# CW32L012 register map
Vendor: Wuhan Xinyuan Semiconductor Co.Ltd; Series: ARMCM0P; File version: 1.2
CPU: CM0+ r0p1, little endian, no MPU, no FPU, VTOR, 2 interrupt priority bits
Registers are 32-bit, read-write, no defined reset value unless marked. A register's access mark holds for its fields unless they carry their own. Offsets are from the block's base; [hi:lo] are bit positions; {n}, {i} and the like mark numbered series; 'fields as' and 'values as' point back to an identical list.

## ATIM
Base 0x40001400
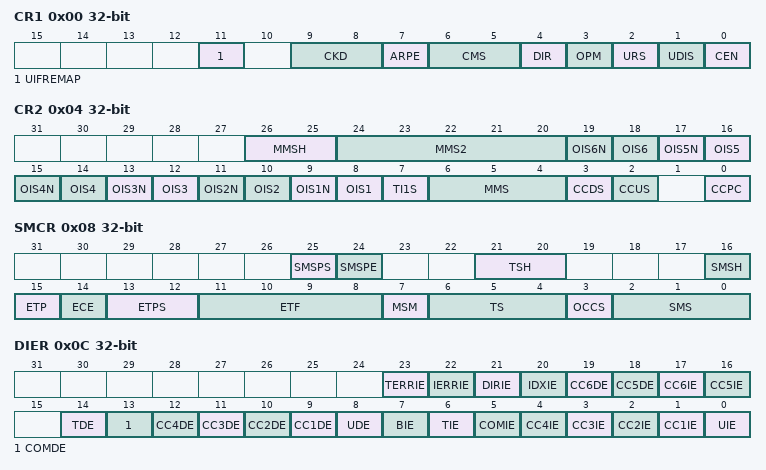
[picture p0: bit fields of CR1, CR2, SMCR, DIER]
0x00 CR1 — Control Register1
  [11] UIFREMAP, [9:8] CKD, [7] ARPE, [6:5] CMS, [4] DIR, [3] OPM, [2] URS, [1] UDIS, [0] CEN
0x04 CR2 — Control Register2
  [26:25] MMSH, [24:20] MMS2, [2n+7] OIS{n}N (n=1..6), [2n+6] OIS{n} (n=1..6), [7] TI1S, [6:4] MMS, [3] CCDS, [2] CCUS, [0] CCPC
0x08 SMCR — Slave Mode Control Register
  [25] SMSPS, [24] SMSPE, [21:20] TSH, [16] SMSH, [15] ETP, [14] ECE, [13:12] ETPS, [11:8] ETF, [7] MSM, [6:4] TS, [3] OCCS, [2:0] SMS
0x0C DIER — Interrupt Enable Register
  [23] TERRIE, [22] IERRIE, [21] DIRIE, [20] IDXIE, [19] CC6DE, [18] CC5DE, [17] CC6IE, [16] CC5IE, [14] TDE, [13] COMDE, [n+8] CC{n}DE (n=1..4), [8] UDE, [7] BIE, [6] TIE, [5] COMIE, [n] CC{n}IE (n=1..4), [0] UIE
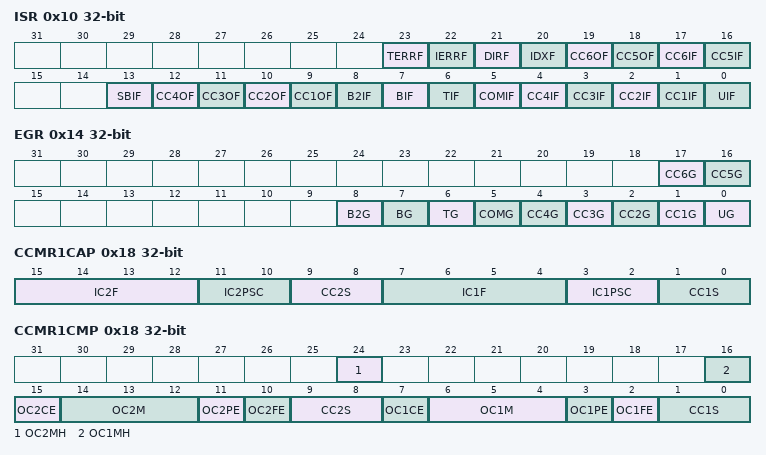
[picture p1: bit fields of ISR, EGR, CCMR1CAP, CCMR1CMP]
0x10 ISR ro — Interrupt status register
  [23] TERRF, [22] IERRF, [21] DIRF, [20] IDXF, [19] CC6OF, [18] CC5OF, [17] CC6IF, [16] CC5IF, [13] SBIF, [n+8] CC{n}OF (n=1..4), [8] B2IF, [7] BIF, [6] TIF, [5] COMIF, [n] CC{n}IF (n=1..4), [0] UIF
0x14 EGR — Event generation register
  [17] CC6G, [16] CC5G, [8] B2G, [7] BG, [6] TG, [5] COMG, [n] CC{n}G (n=1..4), [0] UG
0x18 CCMR1CAP — capture compare mode register 1
  [15:12] IC2F, [11:10] IC2PSC, [9:8] CC2S, [7:4] IC1F, [3:2] IC1PSC, [1:0] CC1S
0x18 CCMR1CMP (alternate view of CCMR1CAP) — capture compare mode register 1
  [24] OC2MH, [16] OC1MH, [15] OC2CE, [14:12] OC2M, [11] OC2PE, [10] OC2FE, [9:8] CC2S, [7] OC1CE, [6:4] OC1M, [3] OC1PE, [2] OC1FE, [1:0] CC1S
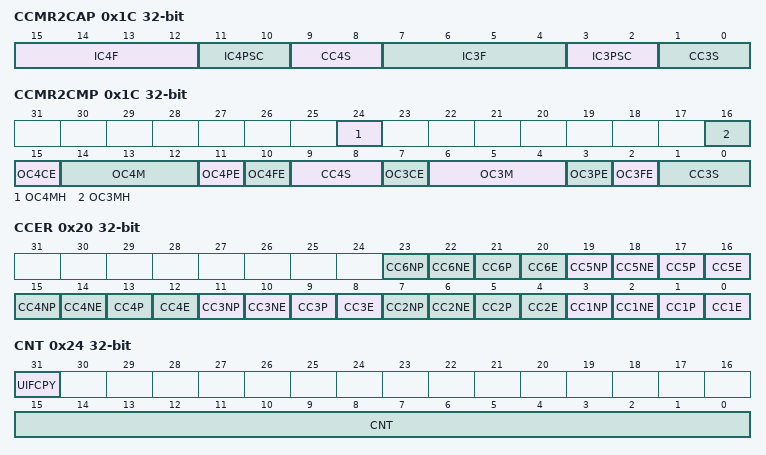
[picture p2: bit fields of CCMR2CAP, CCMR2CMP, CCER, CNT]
0x1C CCMR2CAP — capture compare mode register 2
  [15:12] IC4F, [11:10] IC4PSC, [9:8] CC4S, [7:4] IC3F, [3:2] IC3PSC, [1:0] CC3S
0x1C CCMR2CMP (alternate view of CCMR2CAP) — capture compare mode register 2
  [24] OC4MH, [16] OC3MH, [15] OC4CE, [14:12] OC4M, [11] OC4PE, [10] OC4FE, [9:8] CC4S, [7] OC3CE, [6:4] OC3M, [3] OC3PE, [2] OC3FE, [1:0] CC3S
0x20 CCER — capture compare enable register
  [4n-1] CC{n}NP (n=1..6), [4n-2] CC{n}NE (n=1..6), [4n-3] CC{n}P (n=1..6), [4n-4] CC{n}E (n=1..6)
0x24 CNT — Counter Register
  [31] UIFCPY ro, [15:0] CNT
0x28 PSC — prescaler Register
  [15:0] PSC
0x2C ARR — Auto reload Register
  [15:0] ARR
0x30 RCR — Repetition Counter Register
  [15:0] REP
{0x30+4i} CCR{i} (i=1..4) — capture compare register{i}
  [15:0] CCR{i}
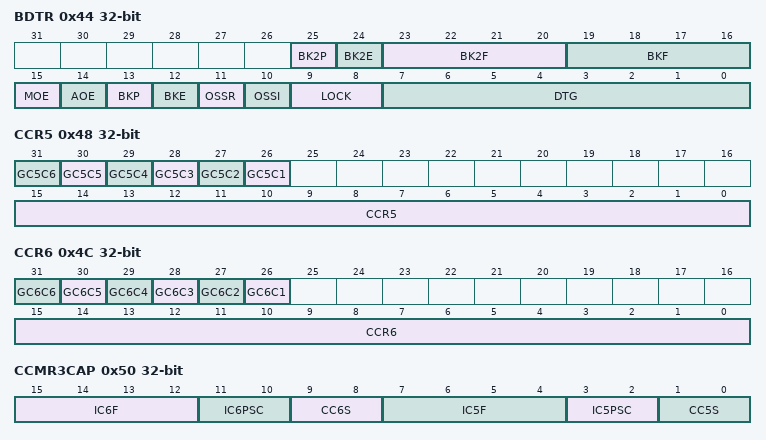
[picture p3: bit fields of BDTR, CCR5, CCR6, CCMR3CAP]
0x44 BDTR — break and dead-time register
  [25] BK2P, [24] BK2E, [23:20] BK2F, [19:16] BKF, [15] MOE, [14] AOE, [13] BKP, [12] BKE, [11] OSSR, [10] OSSI, [9:8] LOCK, [7:0] DTG
0x48 CCR5 — capture compare register5
  [n+25] GC5C{n} (n=1..6), [15:0] CCR5
0x4C CCR6 — capture compare register6
  [n+25] GC6C{n} (n=1..6), [15:0] CCR6
0x50 CCMR3CAP — capture compare mode register 3
  [15:12] IC6F, [11:10] IC6PSC, [9:8] CC6S, [7:4] IC5F, [3:2] IC5PSC, [1:0] CC5S
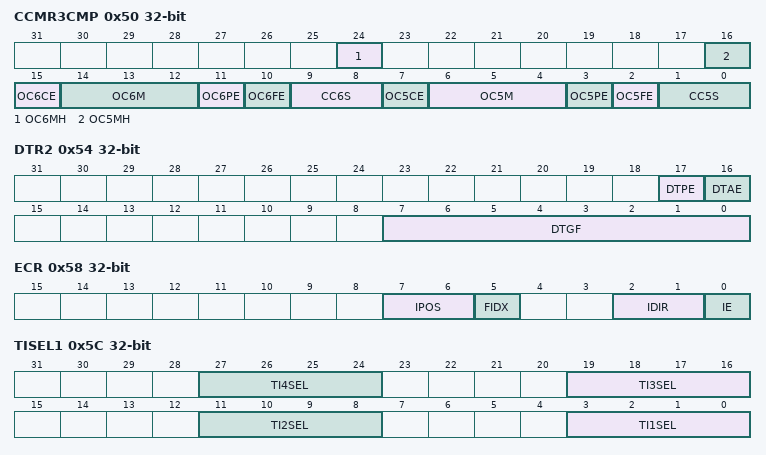
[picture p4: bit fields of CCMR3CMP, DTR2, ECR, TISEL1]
0x50 CCMR3CMP (alternate view of CCMR3CAP) — capture compare mode register 3
  [24] OC6MH, [16] OC5MH, [15] OC6CE, [14:12] OC6M, [11] OC6PE, [10] OC6FE, [9:8] CC6S, [7] OC5CE, [6:4] OC5M, [3] OC5PE, [2] OC5FE, [1:0] CC5S
0x54 DTR2 — dead-time register2
  [17] DTPE, [16] DTAE, [7:0] DTGF
0x58 ECR — Encoder control Register
  [7:6] IPOS, [5] FIDX, [2:1] IDIR, [0] IE
0x5C TISEL1 — Timer Input Select Register1
  [8n-5:8n-8] TI{n}SEL (n=1..4)
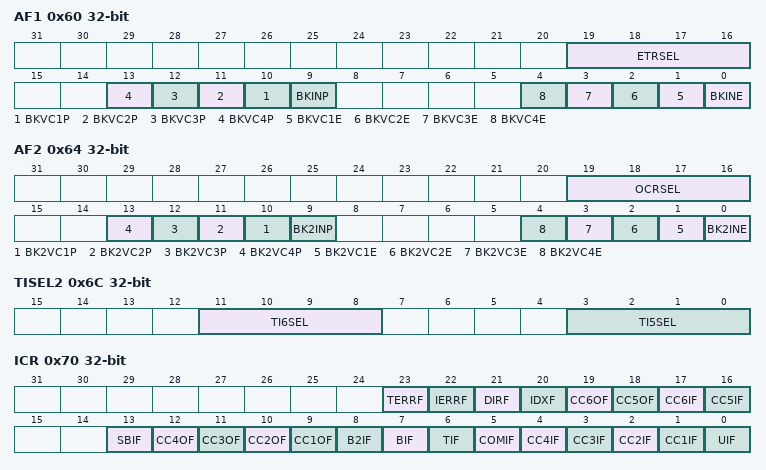
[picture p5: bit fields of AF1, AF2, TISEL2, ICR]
0x60 AF1 — Alternate function Register1
  [19:16] ETRSEL, [n+9] BKVC{n}P (n=1..4), [9] BKINP, [n] BKVC{n}E (n=1..4), [0] BKINE
0x64 AF2 — Alternate function Register2
  [19:16] OCRSEL, [n+9] BK2VC{n}P (n=1..4), [9] BK2INP, [n] BK2VC{n}E (n=1..4), [0] BK2INE
0x6C TISEL2 — Timer Input Select Register2
  [11:8] TI6SEL, [3:0] TI5SEL
0x70 ICR — Interrupt clean register
  fields as ISR

## BGR
Base 0x400000FC
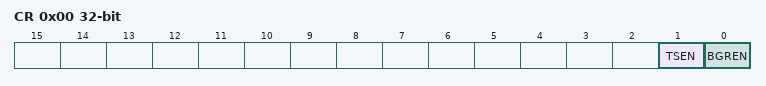
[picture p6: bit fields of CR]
0x00 CR — Control register1
  [1] TSEN, [0] BGREN
